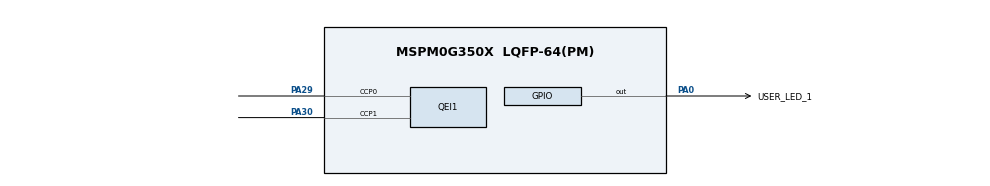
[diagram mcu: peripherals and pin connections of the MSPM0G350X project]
/**
 * @cliArgs --device "MSPM0G350X" --package "LQFP-64(PM)" --part "Default" --product "mspm0_sdk@2.01.00.03"
 * @versions {"tool":"1.20.0+3587"}
 */

/**
 * Import the modules used in this configuration.
 */
const GPIO   = scripting.addModule("/ti/driverlib/GPIO", {}, false);
const GPIO1  = GPIO.addInstance();
const QEI    = scripting.addModule("/ti/driverlib/QEI", {}, false);
const QEI1   = QEI.addInstance();
const SYSCTL = scripting.addModule("/ti/driverlib/SYSCTL");

/**
 * Write custom configuration values to the imported modules.
 */
GPIO1.$name                          = "GPIO_LEDS";
GPIO1.associatedPins[0].$name        = "USER_LED_1";
GPIO1.associatedPins[0].initialValue = "SET";
GPIO1.associatedPins[0].pin.$assign  = "PA0";

const Board = scripting.addModule("/ti/driverlib/Board", {}, false);

QEI1.$name                      = "QEI_0";
QEI1.interrupts                 = ["CC0_UP_EVENT","CC1_UP_EVENT"];
QEI1.interruptPriority          = "0";
QEI1.timerStartTimer            = true;
QEI1.peripheral.$assign         = "TIMG8";
QEI1.peripheral.ccp0Pin.$assign = "PA29";
QEI1.peripheral.ccp1Pin.$assign = "PA30";
QEI1.ccp0PinConfig.$name        = "ti_driverlib_gpio_GPIOPinGeneric0";
QEI1.ccp1PinConfig.$name        = "ti_driverlib_gpio_GPIOPinGeneric1";

SYSCTL.EXCLKSource           = "LFCLK";
SYSCTL.forceDefaultClkConfig = true;
SYSCTL.clockTreeEn           = true;

/**
 * Pinmux solution for unlocked pins/peripherals. This ensures that minor changes to the automatic solver in a future
 * version of the tool will not impact the pinmux you originally saw.  These lines can be completely deleted in order to
 * re-solve from scratch.
 */
Board.peripheral.$suggestSolution          = "DEBUGSS";
Board.peripheral.swclkPin.$suggestSolution = "PA20";
Board.peripheral.swdioPin.$suggestSolution = "PA19";
